VERSION ""

NS_ :

BS_:

BU_: XXX DSU HCU EPS IPAS 0 1 8

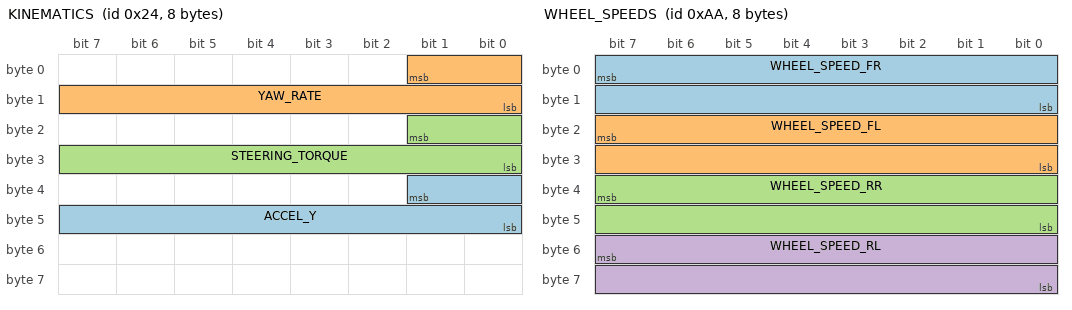
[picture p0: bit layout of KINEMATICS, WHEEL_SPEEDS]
BO_ 36 KINEMATICS: 8 XXX
 SG_ ACCEL_Y : 33|10@0+ (1,-512) [0|65535] "" XXX
 SG_ YAW_RATE : 1|10@0+ (1,-512) [0|65535] "" XXX
 SG_ STEERING_TORQUE : 17|10@0+ (1,-512) [0|65535] "" XXX

BO_ 166 BRAKE: 8 XXX
 SG_ BRAKE_AMOUNT : 7|8@0+ (1,0) [0|255] "" XXX
 SG_ BRAKE_PEDAL : 23|8@0+ (1,0) [0|255] "" XXX

BO_ 170 WHEEL_SPEEDS: 8 XXX
 SG_ WHEEL_SPEED_FR : 7|16@0+ (0.01,-67.67) [0|250] "kph" XXX
 SG_ WHEEL_SPEED_FL : 23|16@0+ (0.01,-67.67) [0|250] "kph" XXX
 SG_ WHEEL_SPEED_RR : 39|16@0+ (0.01,-67.67) [0|250] "kph" XXX
 SG_ WHEEL_SPEED_RL : 55|16@0+ (0.01,-67.67) [0|250] "kph" XXX

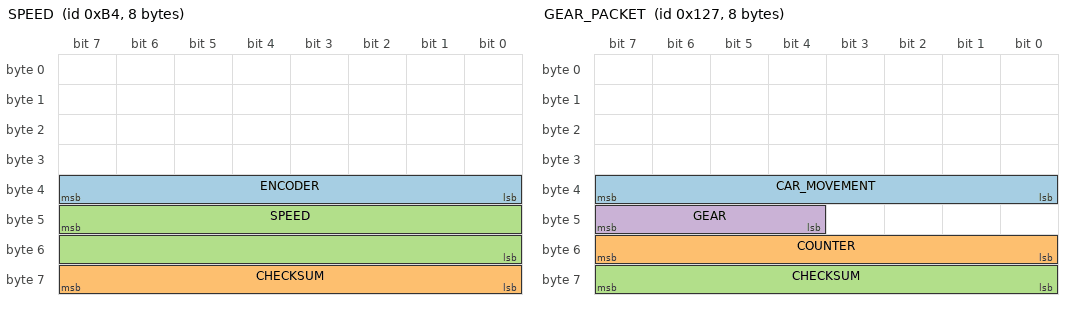
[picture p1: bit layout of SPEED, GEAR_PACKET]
BO_ 180 SPEED: 8 XXX
 SG_ ENCODER : 39|8@0+ (1,0) [0|255] "" XXX
 SG_ CHECKSUM : 63|8@0+ (1,0) [0|255] "" XXX
 SG_ SPEED : 47|16@0+ (0.01,0) [0|250] "kph" XXX

BO_ 295 GEAR_PACKET: 8 XXX
 SG_ CAR_MOVEMENT : 39|8@0- (1,0) [0|255] "" XXX
 SG_ COUNTER : 55|8@0+ (1,0) [0|255] "" XXX
 SG_ CHECKSUM : 63|8@0+ (1,0) [0|255] "" XXX
 SG_ GEAR : 47|4@0+ (1,0) [0|15] "" XXX

BO_ 466 PCM_CRUISE: 8 XXX
 SG_ CRUISE_STATE : 55|4@0+ (1,0) [0|15] "" XXX

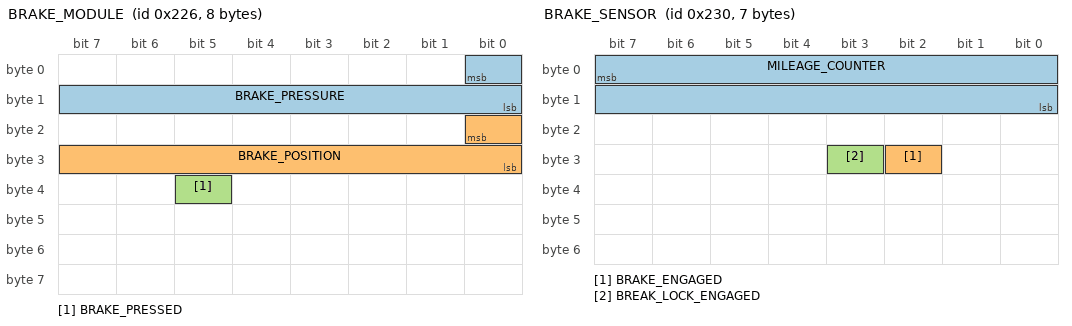
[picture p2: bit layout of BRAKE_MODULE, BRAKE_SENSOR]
BO_ 550 BRAKE_MODULE: 8 XXX
 SG_ BRAKE_PRESSURE : 0|9@0+ (1,0) [0|511] "" XXX
 SG_ BRAKE_POSITION : 16|9@0+ (1,0) [0|511] "" XXX
 SG_ BRAKE_PRESSED : 37|1@0+ (1,0) [0|1] "" XXX

BO_ 552 ACCELEROMETER: 8 XXX
 SG_ ACCEL_Z : 22|15@0- (1,0) [0|32767] "" XXX
 SG_ ACCEL_X : 6|15@0- (0.001,0) [-20|20] "m/s2" XXX

BO_ 560 BRAKE_SENSOR: 7 XXX
 SG_ MILEAGE_COUNTER : 7|16@0+ (0.01,0) [0|655.35] "m" XXX
 SG_ BRAKE_ENGAGED : 26|1@0+ (1,0) [0|1] "" XXX
 SG_ BREAK_LOCK_ENGAGED : 27|1@1+ (1,0) [0|3] "" XXX

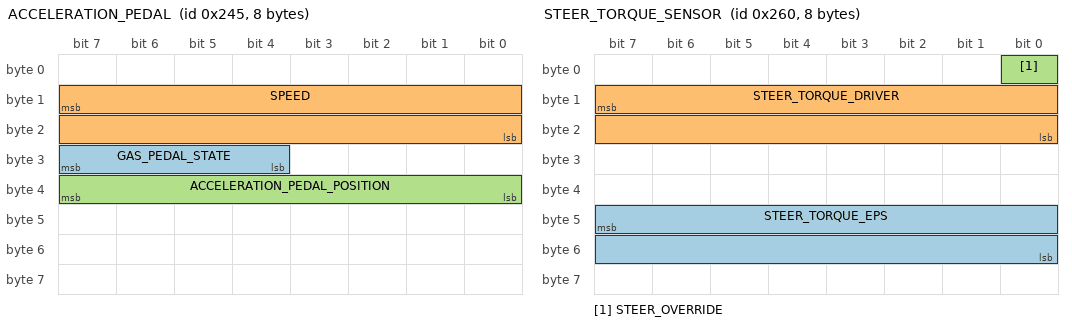
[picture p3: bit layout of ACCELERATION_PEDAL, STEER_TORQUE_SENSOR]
BO_ 581 ACCELERATION_PEDAL: 8 XXX
 SG_ GAS_PEDAL_STATE : 31|4@0+ (1,0) [0|255] "" XXX
 SG_ SPEED : 15|16@0+ (1,0) [0|65535] "" XXX
 SG_ ACCELERATION_PEDAL_POSITION : 39|8@0+ (1,0) [0|255] "" XXX

BO_ 608 STEER_TORQUE_SENSOR: 8 XXX
 SG_ STEER_TORQUE_EPS : 47|16@0- (0.5,0) [0|65535] "" XXX
 SG_ STEER_TORQUE_DRIVER : 15|16@0- (1,0) [-32768|32767] "" XXX
 SG_ STEER_OVERRIDE : 0|1@0+ (1,0) [0|1] "" XXX

BO_ 610 EPS_STATUS: 5 EPS
 SG_ STATE : 3|4@0+ (1,0) [0|15] "" XXX

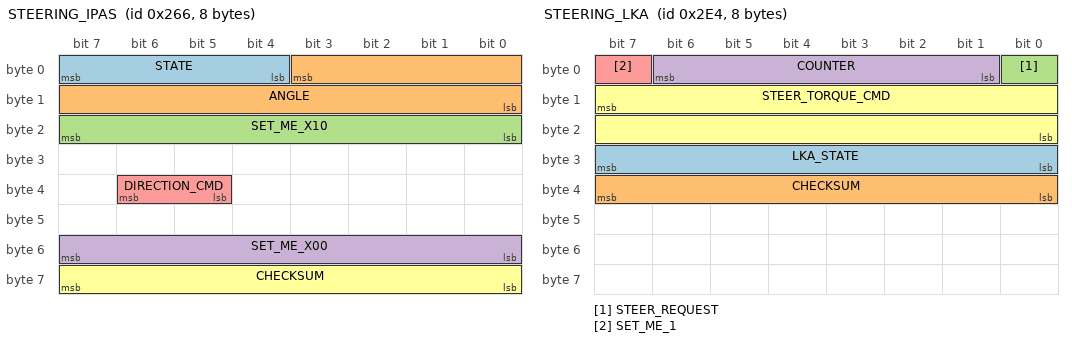
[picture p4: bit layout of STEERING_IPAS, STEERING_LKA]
BO_ 614 STEERING_IPAS: 8 IPAS
 SG_ STATE : 7|4@0+ (1,0) [0|15] "" XXX
 SG_ ANGLE : 3|12@0- (1,0) [0|16777215] "" XXX
 SG_ SET_ME_X10 : 23|8@0+ (1,0) [0|255] "" XXX
 SG_ SET_ME_X00 : 55|8@0+ (1,0) [0|255] "" XXX
 SG_ DIRECTION_CMD : 38|2@0+ (1,0) [0|3] "" XXX
 SG_ CHECKSUM : 63|8@0+ (1,0) [0|255] "" XXX

BO_ 643 PRE_COLLISION: 8 XXX

BO_ 740 STEERING_LKA: 8 XXX
 SG_ LKA_STATE : 31|8@0+ (1,0) [0|255] "" XXX
 SG_ CHECKSUM : 39|8@0+ (1,0) [0|255] "" XXX
 SG_ STEER_REQUEST : 0|1@0+ (1,0) [0|1] "" XXX
 SG_ COUNTER : 6|6@0+ (1,0) [0|63] "" XXX
 SG_ SET_ME_1 : 7|1@0+ (1,0) [0|1] "" XXX
 SG_ STEER_TORQUE_CMD : 15|16@0- (1,0) [0|65535] "" XXX

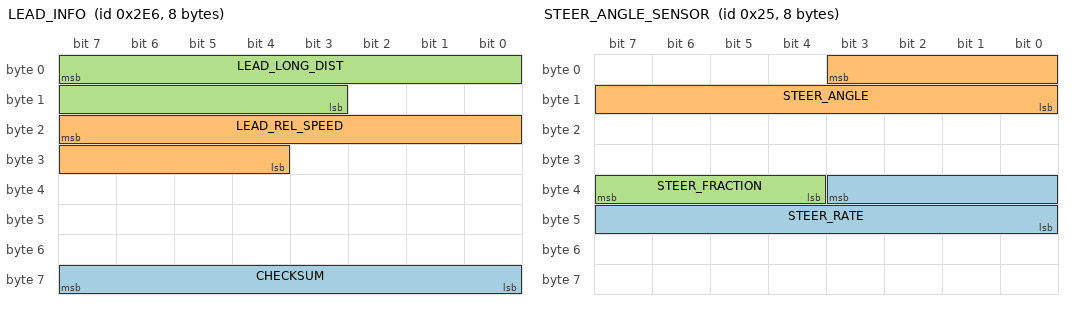
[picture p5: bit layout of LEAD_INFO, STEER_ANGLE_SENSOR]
BO_ 742 LEAD_INFO: 8 DSU
 SG_ CHECKSUM : 63|8@0+ (1,0) [0|255] "" HCU
 SG_ LEAD_REL_SPEED : 23|12@0- (0.025,0) [-100|100] "m/s" HCU
 SG_ LEAD_LONG_DIST : 7|13@0+ (0.05,0) [0|300] "m" HCU

BO_ 835 ACC_CONTROL: 8 DSU
 SG_ ACCEL_CMD : 7|16@0- (0.001,0) [-20|20] "m/s2" HCU

BO_ 1556 STEERING_LEVERS: 8 XXX
 SG_ TURN_SIGNALS : 29|2@0+ (1,0) [0|3] "" XXX

BO_ 37 STEER_ANGLE_SENSOR: 8 XXX
 SG_ STEER_RATE : 35|12@0- (1,0) [-2000|2000] "deg/s" XXX
 SG_ STEER_ANGLE : 3|12@0- (1.5,0) [-500|500] "deg" XXX
 SG_ STEER_FRACTION : 39|4@0- (0.1,0) [-0.7|0.7] "deg" XXX

BO_ 467 PCM_CRUISE_2: 8 XXX
 SG_ MAIN_ON : 15|1@0+ (1,0) [0|1] "" XXX
 SG_ SET_SPEED : 23|8@0+ (1,0) [0|255] "kph" XXX

BO_ 921 PCM_CRUISE_SM: 8 XXX
 SG_ MAIN_ON : 4|1@0+ (1,0) [0|1] "" XXX
 SG_ CRUISE_CONTROL_STATE : 11|4@0+ (1,0) [0|15] "" XXX

BO_ 951 ESP_CONTROL: 8 ESP
 SG_ TC_DISABLED : 13|1@0+ (1,0) [0|1] "" XXX

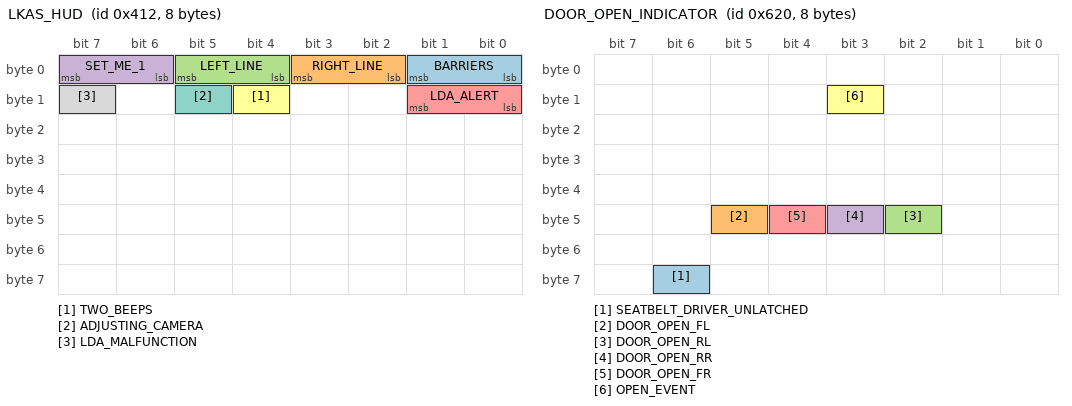
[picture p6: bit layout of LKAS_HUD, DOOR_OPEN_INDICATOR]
BO_ 1042 LKAS_HUD: 8 XXX
 SG_ BARRIERS : 1|2@0+ (1,0) [0|3] "" XXX
 SG_ RIGHT_LINE : 3|2@0+ (1,0) [0|3] "" XXX
 SG_ LEFT_LINE : 5|2@0+ (1,0) [0|3] "" XXX
 SG_ SET_ME_1 : 7|2@0+ (1,0) [0|3] "" XXX
 SG_ LDA_ALERT : 9|2@0+ (1,0) [0|3] "" XXX
 SG_ TWO_BEEPS : 12|1@0+ (1,0) [0|1] "" XXX
 SG_ ADJUSTING_CAMERA : 13|1@0+ (1,0) [0|1] "" XXX
 SG_ LDA_MALFUNCTION : 15|1@0+ (1,0) [0|1] "" XXX

BO_ 1568 DOOR_OPEN_INDICATOR: 8 XXX
 SG_ SEATBELT_DRIVER_UNLATCHED : 62|1@0+ (1,0) [0|1] "" XXX
 SG_ DOOR_OPEN_FL : 45|1@0+ (1,0) [0|1] "" XXX
 SG_ DOOR_OPEN_RL : 42|1@0+ (1,0) [0|1] "" XXX
 SG_ DOOR_OPEN_RR : 43|1@0+ (1,0) [0|1] "" XXX
 SG_ DOOR_OPEN_FR : 44|1@0+ (1,0) [0|1] "" XXX
 SG_ OPEN_EVENT : 11|1@1+ (1,0) [0|15] "" XXX

BO_ 1564 CHK_SLOW_COUNTER: 8 XXX

BO_ 1190 NEW_MSG_1: 8 XXX
 SG_ TWO_BIT_COUNTER : 7|2@0+ (1,0) [0|3] "" XXX
 SG_ NEW_SIGNAL_1 : 23|4@0+ (1,0) [0|15] "" XXX
 SG_ NEW_SIGNAL_2 : 31|4@0+ (1,0) [0|15] "" XXX
 SG_ NEW_SIGNAL_3 : 39|4@0+ (1,0) [0|15] "" XXX
 SG_ NEW_SIGNAL_4 : 47|4@0+ (1,0) [0|15] "" XXX
 SG_ NEW_SIGNAL_6 : 24|7@1+ (1,0) [0|15] "" XXX
 SG_ NEW_SIGNAL_7 : 32|7@1+ (1,0) [0|15] "" XXX
 SG_ NEW_SIGNAL_8 : 40|7@1+ (1,0) [0|15] "" XXX
 SG_ NEW_SIGNAL_9 : 48|8@1+ (1,0) [0|15] "" XXX
 SG_ NEW_SIGNAL_5 : 16|7@1+ (1,0) [0|15] "" XXX

BO_ 944 NEW_MSG_2: 8 XXX
 SG_ NEW_SIGNAL_1 : 8|8@1+ (1,0) [0|15] "" XXX

BO_ 1595 NEW_MSG_3: 8 XXX
 SG_ COUNTER : 55|16@0+ (1,0) [0|65535] "" XXX

BO_ 1552 NEW_MSG_4: 8 XXX
 SG_ COUNTER : 16|4@1+ (1,0) [0|15] "" XXX
 SG_ NEW_SIGNAL_1 : 4|4@1+ (1,0) [0|255] "" XXX
 SG_ NEW_SIGNAL_2 : 0|7@1+ (1,0) [0|15] "" XXX

BO_ 452 ENGINE_GAS: 8 XXX
 SG_ _CHECKSUM : 63|8@0- (1,0) [0|255] "" XXX
 SG_ RPM : 7|16@0+ (1,0) [0|65535] "" XXX

BO_ 800 _ACCELERATION: 8 XXX
 SG_ ACCELERATION : 39|8@0- (1,0) [0|255] "" XXX

BO_ 548 BREAK_PEDAL_SENSOR: 8 XXX
 SG_ BREAK_ENGAGE : 5|1@0+ (1,0) [0|1] "," 8
 SG_ BREAK_PEDAL_POSITION : 47|8@0+ (1,0) [0|255] "" 1

BO_ 182 SPEED2: 4 XXX
 SG_ CHECKSUM : 24|8@1- (1,0) [0|65535] "" XXX
 SG_ SPEED : 7|16@0+ (0.01,0) [0|65535] "kph" XXX

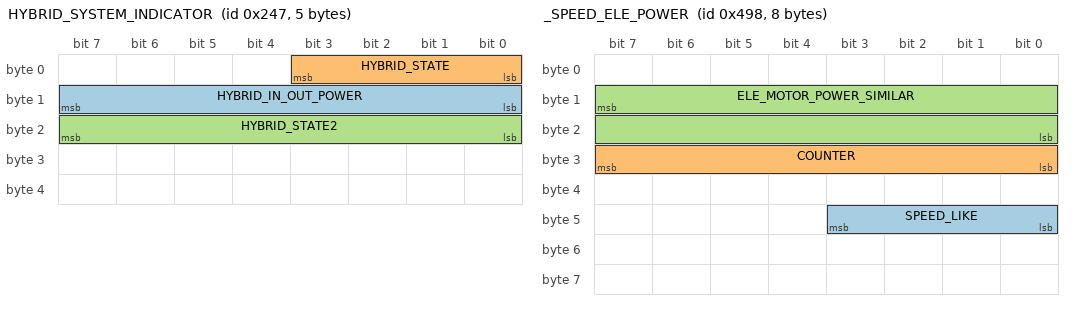
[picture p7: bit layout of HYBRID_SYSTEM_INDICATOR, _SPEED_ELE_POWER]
BO_ 583 HYBRID_SYSTEM_INDICATOR: 5 XXX
 SG_ HYBRID_IN_OUT_POWER : 15|8@0- (1,0) [0|65535] "" XXX
 SG_ HYBRID_STATE : 0|4@1+ (1,0) [0|7] "" XXX
 SG_ HYBRID_STATE2 : 23|8@0+ (1,0) [0|255] "" XXX

BO_ 1176 _SPEED_ELE_POWER: 8 XXX
 SG_ SPEED_LIKE : 43|4@0+ (1,0) [0|255] "" XXX
 SG_ COUNTER : 24|8@1+ (1,0) [0|65535] "" XXX
 SG_ ELE_MOTOR_POWER_SIMILAR : 15|16@0+ (1,0) [0|255] "" XXX

BO_ 947 ELECTRIC_MOTOR: 8 XXX
 SG_ _POWER : 23|8@0- (1,0) [0|255] "" XXX

BO_ 979 _ACC_SPEED: 8 XXX
 SG_ SPEED_RELATED : 7|16@0+ (1,0) [0|65535] "" XXX

BO_ 1177 NEW_MSG_5: 8 XXX
 SG_ NEW_SIGNAL_1 : 23|16@0- (1,0) [0|65535] "" XXX
 SG_ _GAS_PEDALACCCEL : 0|16@1- (1,0) [0|255] "" XXX

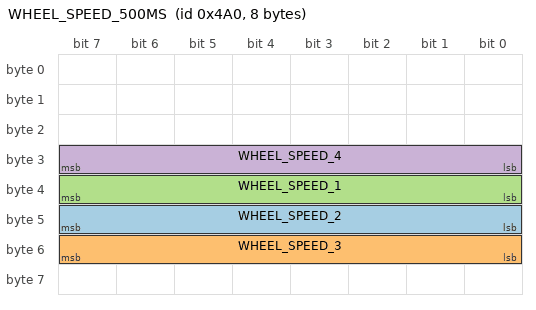
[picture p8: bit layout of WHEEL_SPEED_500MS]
BO_ 1184 WHEEL_SPEED_500MS: 8 XXX
 SG_ WHEEL_SPEED_2 : 47|8@0+ (1,0) [0|255] "" XXX
 SG_ WHEEL_SPEED_3 : 55|8@0+ (1,0) [0|255] "" XXX
 SG_ WHEEL_SPEED_1 : 39|8@0+ (1,0) [0|255] "" XXX
 SG_ WHEEL_SPEED_4 : 31|8@0+ (1,0) [0|255] "" XXX

BO_ 1179 _THROTTLE: 8 XXX
 SG_ POSITION_THROTTLE : 7|8@0+ (1,0) [0|255] "" XXX

BO_ 1574 NEW_MSG_6: 8 XXX
 SG_ STATE_DOORS : 21|2@0+ (1,0) [0|3] "" XXX

BO_ 32 NEW_MSG_7: 8 XXX
 SG_ NEW_SIGNAL_2 : 23|8@0+ (1,0) [0|255] "" XXX
 SG_ NEW_SIGNAL_1 : 55|8@0+ (1,0) [0|255] "" XXX

BO_ 950 NEW_MSG_8: 8 XXX
 SG_ STATE : 8|8@1+ (1,0) [0|255] "" XXX
 SG_ DRIVE_STATE : 47|8@0+ (1,0) [0|255] "" XXX

BO_ 1570 COMBINATION_METER_DISPLAY: 8 XXX
 SG_ STATE2 : 31|8@0+ (1,0) [0|255] "" XXX
 SG_ STATE : 23|8@0+ (1,0) [0|255] "" XXX

BO_ 865 NEW_MSG_9: 8 XXX
 SG_ LOOK_LIKE_SPEED : 15|8@0+ (1,0) [0|255] "" XXX
 SG_ GAS_PEDAL_SPEED : 23|8@0+ (1,0) [0|255] "" XXX

CM_ SG_ 36 ACCEL_Y "unit is tbd";
CM_ SG_ 36 YAW_RATE "verify";
CM_ SG_ 36 STEERING_TORQUE "does not seem the steer torque, tbd";
CM_ SG_ 550 BRAKE_PRESSURE "seems prop to pedal force";
CM_ SG_ 550 BRAKE_POSITION "seems proportional to pedal displacement, unclear the max value of 0x1c8";
CM_ SG_ 560 BRAKE_ENGAGED "double check";
CM_ SG_ 608 STEER_TORQUE_EPS "0.5 factor to be comparable with STEER_TORQUE_CMD";
CM_ SG_ 608 STEER_TORQUE_DRIVER "driver torque";
CM_ SG_ 608 STEER_OVERRIDE "set when driver torque exceeds a certain value";
CM_ SG_ 610 STATE "0x01 - not engaged 0x05 engaged";
CM_ SG_ 614 ANGLE "set to measured angle when ipas control isn't active";
CM_ SG_ 37 STEER_RATE "factor is tbd";
CM_ SG_ 37 STEER_FRACTION "1/15th of the signal STEER_ANGLE, which is 1.5 deg; note that 0x8 is never set";
CM_ SG_ 467 SET_SPEED "43 kph are shown as 28mph, so conversion isnt perfect";
CM_ SG_ 1042 SET_ME_1 "unclear what this is, nut it's always 1 in drive traces";
CM_ SG_ 1574 STATE_DOORS "from other DBC - not tested";
VAL_ 295 GEAR 0 "P" 1 "R" 2 "N" 3 "D" 4 "B" ;
VAL_ 466 CRUISE_STATE 8 "active" 7 "standstill" 1 "off" ;
VAL_ 610 STATE 5 "override" 3 "enabled" 1 "disabled" ;
VAL_ 614 STATE 3 "enabled" 1 "disabled" ;
VAL_ 614 DIRECTION_CMD 3 "right" 2 "center" 1 "left" ;
VAL_ 1556 TURN_SIGNALS 3 "none" 2 "right" 1 "left" ;
VAL_ 921 CRUISE_CONTROL_STATE 2 "disabled" 11 "hold" 10 "hold_waiting_user_cmd" 6 "enabled" ;
VAL_ 1042 BARRIERS 3 "both" 2 "right" 1 "left" 0 "none" ;
VAL_ 1042 RIGHT_LINE 3 "orange" 2 "double" 1 "solid" 0 "none" ;
VAL_ 1042 LEFT_LINE 3 "orange" 2 "double" 1 "solid" 0 "none" ;
VAL_ 1042 LDA_ALERT 3 "hold with continuous beep" 2 "LDA unavailable" 1 "hold" 0 "none" ;
CM_ "CHFFR_METRIC 37 STEER_ANGLE STEER_ANGLE 0.36 180";
